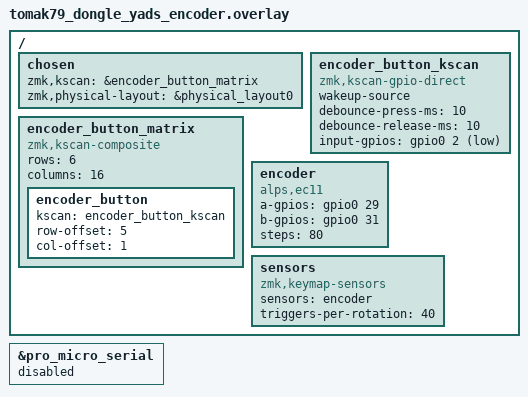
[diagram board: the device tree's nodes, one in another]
#include <behaviors.dtsi>
#include <dt-bindings/zmk/matrix_transform.h>
#include <dt-bindings/zmk/keys.h>
#include "tomak79_layout_only.dtsi"

/ {
    chosen {
        zmk,kscan = &encoder_button_matrix;
        zmk,physical-layout = &physical_layout0;
    };

    encoder_button_kscan: encoder_button_kscan {
        compatible = "zmk,kscan-gpio-direct";
        wakeup-source;
        debounce-press-ms = <10>;
        debounce-release-ms = <10>;
        input-gpios = <&gpio0 2 (GPIO_ACTIVE_LOW | GPIO_PULL_UP)>;
    };

    encoder_button_matrix: encoder_button_matrix {
        compatible = "zmk,kscan-composite";
        rows = <6>;
        columns = <16>;

        encoder_button {
            kscan = <&encoder_button_kscan>;
            row-offset = <5>;
            col-offset = <1>;
        };
    };

    encoder: encoder {
        compatible = "alps,ec11";
        a-gpios = <&gpio0 29 (GPIO_ACTIVE_HIGH | GPIO_PULL_UP)>;
        b-gpios = <&gpio0 31 (GPIO_ACTIVE_HIGH | GPIO_PULL_UP)>;
        steps = <80>;
        status = "okay";
    };

    sensors: sensors {
        compatible = "zmk,keymap-sensors";
        sensors = <&encoder>;
        triggers-per-rotation = <40>;
    };
};

&pro_micro_serial {
    status = "disabled";
};
